# EFM32GG12B410F1024IL112 register map
File version: 4.0.0
CPU: CM4 r0p1, little endian, MPU, FPU, 3 interrupt priority bits
Registers are 32-bit, read-write, reset 0x0 unless marked. A register's access mark holds for its fields unless they carry their own. Offsets are from the block's base; [hi:lo] are bit positions; {n}, {i} and the like mark numbered series; 'fields as' and 'values as' point back to an identical list.

## PRS
Base 0x400E6000
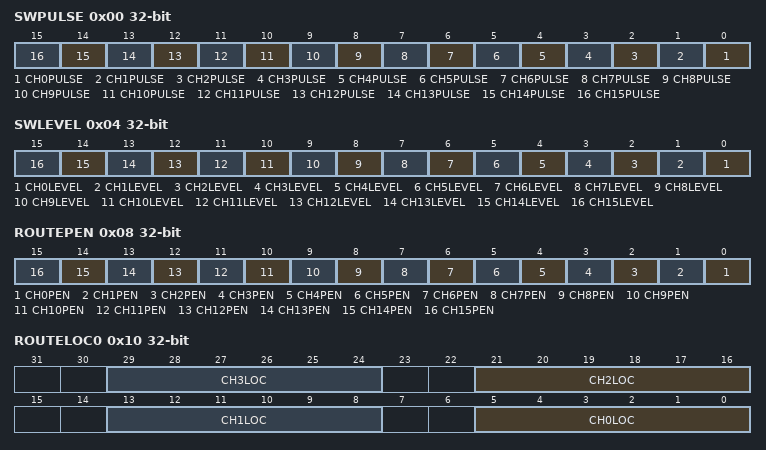
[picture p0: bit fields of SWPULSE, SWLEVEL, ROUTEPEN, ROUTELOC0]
0x00 SWPULSE wo — Software Pulse Register
  [n] CH{n}PULSE (n=0..15) — Channel {n} Pulse Generation
0x04 SWLEVEL — Software Level Register
  [n] CH{n}LEVEL (n=0..15) — Channel {n} Software Level
0x08 ROUTEPEN — I/O Routing Pin Enable Register
  [n] CH{n}PEN (n=0..15) — CH{n} Pin Enable
0x10 ROUTELOC0 — I/O Routing Location Register
  [all] fields
    {v}=LOC{v} (Location {v}) (v=0..3)
  [8n+5:8n] CH{n}LOC (n=0..3) — I/O Location
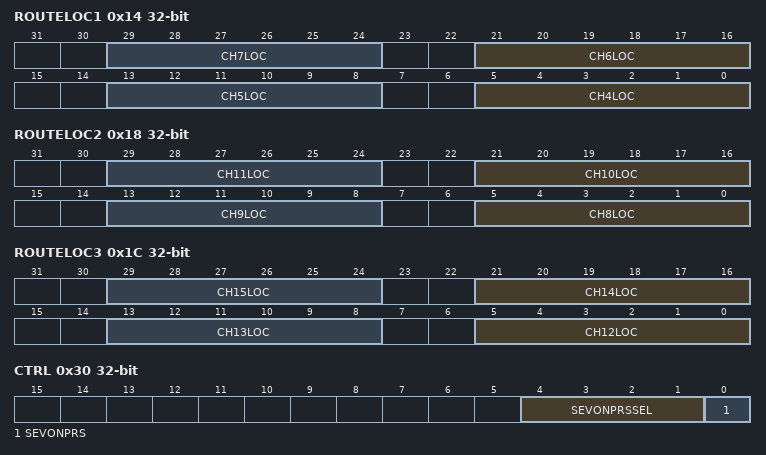
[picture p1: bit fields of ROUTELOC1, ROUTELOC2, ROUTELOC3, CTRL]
0x14 ROUTELOC1 — I/O Routing Location Register
  [all] fields
    0=LOC0 (Location 0); 1=LOC1 (Location 1); 2=LOC2 (Location 2)
  [8n-27:8n-32] CH{n}LOC (n=4..7) — I/O Location
0x18 ROUTELOC2 — I/O Routing Location Register
  [all] fields
    values as the fields of ROUTELOC1
  [8n-59:8n-64] CH{n}LOC (n=8..11) — I/O Location
0x1C ROUTELOC3 — I/O Routing Location Register
  [all] fields
    values as the fields of ROUTELOC1
  [8n-91:8n-96] CH{n}LOC (n=12..15) — I/O Location
0x30 CTRL — Control Register
  [4:1] SEVONPRSSEL — SEVONPRS PRS Channel Select
    {v}=PRSCH{v} (PRS Channel {v} selected) (v=0..15)
  [0] SEVONPRS — Set Event on PRS
0x34 DMAREQ0 — DMA Request 0 Register
  [9:6] PRSSEL — DMA Request 0 PRS Channel Select
    {v}=PRSCH{v} (PRS Channel {v} selected) (v=0..15)
0x38 DMAREQ1 — DMA Request 1 Register
  [9:6] PRSSEL — DMA Request 1 PRS Channel Select
    {v}=PRSCH{v} (PRS Channel {v} selected) (v=0..15)
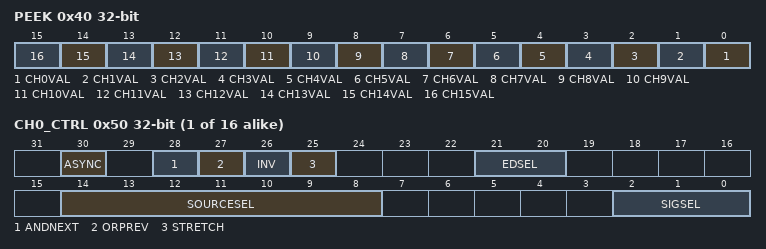
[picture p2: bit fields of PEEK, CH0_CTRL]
0x40 PEEK ro — PRS Channel Values
  [n] CH{n}VAL (n=0..15) — Channel {n} Current Value
{0x50+4i} CH{i}_CTRL (i=0..15) — Channel Control Register
  [30] ASYNC — Asynchronous Reflex
  [28] ANDNEXT
  [27] ORPREV — Or Previous
  [26] INV — Invert Channel
  [25] STRETCH — Stretch Channel Output
  [21:20] EDSEL — Edge Detect Select
    0=OFF (Signal is left as it is); 1=POSEDGE (A one HFCLK cycle pulse is generated for every positive edge of the incoming signal); 2=NEGEDGE (A one HFCLK clock cycle pulse is generated for every negative edge of the incoming signal); 3=BOTHEDGES (A one HFCLK clock cycle pulse is generated for every edge of the incoming signal)
  [14:8] SOURCESEL — Source Select
    0=NONE (No source selected); 1=PRSL (Peripheral Reflex System); 2=PRS (Peripheral Reflex System); 4=ACMP0 (Analog Comparator 0); 5=ACMP1 (Analog Comparator 1); 6=ADC0 (Analog to Digital Converter 0); 7=RTC (Real-Time Counter); 8=RTCC (Real-Time Counter and Calendar); 9=GPIOL (General purpose Input/Output); 10=GPIOH (General purpose Input/Output); 11=LETIMER0 (Low Energy Timer 0); 12=LETIMER1 (Low Energy Timer 1); 13=PCNT0 (Pulse Counter 0); 14=PCNT1 (Pulse Counter 1); 15=PCNT2 (Pulse Counter 2); 16=CRYOTIMER; 17=CMU (Clock Management Unit); 23=VDAC0 (Digital to Analog Converter 0); 24=LESENSEL (Low Energy Sensor Interface); 25=LESENSEH (Low Energy Sensor Interface); 26=LESENSED (Low Energy Sensor Interface); 27=LESENSE (Low Energy Sensor Interface); 28=ACMP2 (Analog Comparator 2); 29=ADC1 (Analog to Digital Converter 0); {v}=USART{v-48} (Universal Synchronous/Asynchronous Receiver/Transmitter {v-48}) (v=48..52); 54=UART0 (Universal Asynchronous Receiver/Transmitter 0); 55=UART1 (Universal Asynchronous Receiver/Transmitter 1); 60=TIMER0; 61=TIMER1; 62=TIMER2; 64=USB (Universal Serial Bus Interface); 67=CM4; 80=TIMER3; 82=WTIMER0 (Wide Timer 0); 83=WTIMER1 (Wide Timer 0); 121=PDM (PDM Interface)
  [2:0] SIGSEL — Signal Select

## FPUEH
Base 0x40001000
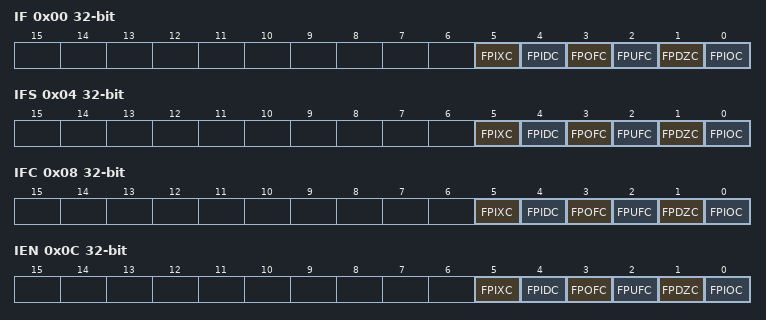
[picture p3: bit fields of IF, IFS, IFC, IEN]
0x00 IF ro — Interrupt Flag Register
  [5] FPIXC — FPU inexact exception
  [4] FPIDC — FPU input denormal exception
  [3] FPOFC — FPU overflow exception
  [2] FPUFC — FPU underflow exception
  [1] FPDZC — FPU divide-by-zero exception
  [0] FPIOC — FPU invalid operation
0x04 IFS wo — Interrupt Flag Set Register
  [5] FPIXC — Set FPIXC Interrupt Flag
  [4] FPIDC — Set FPIDC Interrupt Flag
  [3] FPOFC — Set FPOFC Interrupt Flag
  [2] FPUFC — Set FPUFC Interrupt Flag
  [1] FPDZC — Set FPDZC Interrupt Flag
  [0] FPIOC — Set FPIOC Interrupt Flag
0x08 IFC wo — Interrupt Flag Clear Register
  [5] FPIXC — Clear FPIXC Interrupt Flag
  [4] FPIDC — Clear FPIDC Interrupt Flag
  [3] FPOFC — Clear FPOFC Interrupt Flag
  [2] FPUFC — Clear FPUFC Interrupt Flag
  [1] FPDZC — Clear FPDZC Interrupt Flag
  [0] FPIOC — Clear FPIOC Interrupt Flag
0x0C IEN — Interrupt Enable Register
  [5] FPIXC — FPIXC Interrupt Enable
  [4] FPIDC — FPIDC Interrupt Enable
  [3] FPOFC — FPOFC Interrupt Enable
  [2] FPUFC — FPUFC Interrupt Enable
  [1] FPDZC — FPDZC Interrupt Enable
  [0] FPIOC — FPIOC Interrupt Enable

## Notices in the file
# License
Copyright 2021 Silicon Laboratories Inc. www.silabs.com
SPDX-License-Identifier: Zlib
The licensor of this software is Silicon Laboratories Inc.
This software is provided 'as-is', without any express or implied
warranty. In no event will the authors be held liable for any damages
arising from the use of this software.
Permission is granted to anyone to use this software for any purpose,
including commercial applications, and to alter it and redistribute it
freely, subject to the following restrictions:
1. The origin of this software must not be misrepresented; you must not
claim that you wrote the original software. If you use this software
in a product, an acknowledgment in the product documentation would be
appreciated but is not required.
2. Altered source versions must be plainly marked as such, and must not be
misrepresented as being the original software.
3. This notice may not be removed or altered from any source distribution.
